AUTOSAR XML (schema 00046)
standard types defined: uint8
package /MyDataTypes
  impl type My_uint8: category=VALUE, base-type=uint8, range phys 0..255, raw 0..255
package /INT_PKG
  sender receiver interface IN_SR_DoorLock
    data DoorState: type=My_uint8, init-value=0
  client server interface IN_CS_LED
    operation led_switch: possible-error=[E_OK, E_NOK]
      arg door_state: type=My_uint8, direction=IN
    error E_OK: error-code=0
    error E_NOK: error-code=1
package /Software_Com_PKG
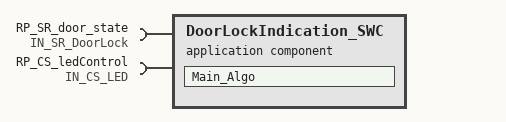
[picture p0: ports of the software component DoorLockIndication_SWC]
  application sw component type DoorLockIndication_SWC
    require port RP_SR_door_state: required-interface=IN_SR_DoorLock
    require port RP_CS_ledControl: required-interface=IN_CS_LED
    behavior IB_DoorLockIndication_SWC
      runnable Main_Algo: symbol=DoorLockIndication_SWC_runable
        data-receive-point-by-arguments:
          access door_state: accessed-variable=RP_SR_door_state.DoorState
        sync call SCALL_led_switch: operation=RP_CS_ledControl.led_switch
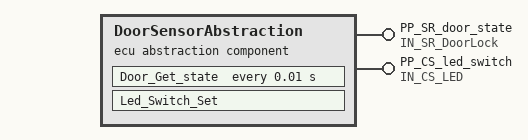
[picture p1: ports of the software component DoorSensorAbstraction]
  ecu abstraction sw component type DoorSensorAbstraction
    provide port PP_SR_door_state: provided-interface=IN_SR_DoorLock
    provide port PP_CS_led_switch: provided-interface=IN_CS_LED
    behavior IB_DoorSensorAbstraction
      timing event TIM_EVE_10ms: start-on-event=Door_Get_state, period=0.01
      operation invoked event DIO_led_switch: start-on-event=Led_Switch_Set, operation=PP_CS_led_switch.led_switch
      runnable Door_Get_state: symbol=Door_Get_state_runnable
        data-write-access:
          access DS_value: accessed-variable=PP_SR_door_state.DoorState
      runnable Led_Switch_Set: symbol=Led_Switch_Set_runnable
package /Compostion_SWC_PKGs
  composition sw component type Comp_PKG
    component Comp_ECU_Abstraction: type=DoorSensorAbstraction
    component Comp_DoorLook_App: type=DoorLockIndication_SWC
    connect Comp_ECU_Abstraction.PP_SR_door_state -> Comp_DoorLook_App.RP_SR_door_state
    connect Comp_ECU_Abstraction.PP_CS_led_switch -> Comp_DoorLook_App.RP_CS_ledControl
